AUTOSAR XML (schema 4-2-2)
standard types defined: UInt16, UInt32, UInt8, sint16, sint32, sint8, uint16, uint32, uint8
package /AUTOLIV/GlobalDictionary/ApplicationDataTypes
  25 x app type, all with category=VALUE, sw-calibration-access=READ-ONLY:
    UInt16_Appl: range phys 0..65535, raw 0..65535
    UInt32_Appl: range phys 0..4294967295, raw 0..4294967295
    UInt8_Appl: range phys 0..255, raw 0..255
    b8AlgorithmFlagsStatusType_Appl: compu {85=KB8_ALGO_FLAG_OFF (default), 170=KB8_ALGO_FLAG_ON (default)}, range raw 0..255
    b8BooleanType_Appl: compu {85=KU8_FALSE (default), 170=KU8_TRUE (default)}, range raw 0..255
    b8DefectStatusType_Appl: range raw 0..255
    b8IsCarAccelerationLowType_Appl: compu {85=KU8_FALSE (default), 170=KU8_TRUE (default)}, range raw 0..255  # Type of information about car acceleration state : low or not.
    b8IsCarCrankingActiveType_Appl: compu {85=KU8_FALSE (default), 170=KU8_TRUE (default)}, range raw 0..255  # To know if the car engine is cranking or not.
    b8IsCarCrashDetectedType_Appl: compu {85=KU8_FALSE (default), 170=KU8_TRUE (default)}, range raw 0..255  # Contains the information whether a car crash is detected or not.
    b8PyroActivationStatusType_Appl: compu {85=KB8_PYRO_DEVICE_NOT_ACTIVATED (default), 170=KB8_PYRO_DEVICE_ACTIVATED (default)} "List of status for the pyro device", range raw 0..255  # Type definition for the pyro device activation status
    s16AccelerationPedalPositionRateType_Appl: compu {raw=phys*2}, range raw -32768..32767
    s16AccelerationType_Appl: compu {raw=phys*16}, range raw -32768..32767
    s16AngleRateType_Appl: compu {raw=phys*256}, range raw -32768..32767
    s16BeltPosition_degType_Appl: range raw -32768..32767  # Belt position in °
    s16BeltPosition_mmType_Appl: range phys -32768..32767, raw -32768..32767  # Belt position in mm
    s16BrakePressureRateType_Appl: compu {raw=phys*16}, range raw -32768..32767
    s16HWAngleType_Appl: compu {raw=phys*16}, range raw -32768..32767
    s16HWRateType_Appl: compu {raw=phys*16}, range raw -32768..32767
    s16InternalTemperature_deg_Type_Appl: range phys -32768..32767, raw -32768..32767  # Type definition for the internal temperature in degrees Celcius
    s16MotorPowerOrderType_Appl: range phys -32768..32767, raw -32768..32767  # % of motor power [-X; +X] x = 6400
    s32BeltSpeed_deg_sType_Appl: range phys -2147483648..2147483647, raw -2147483648..2147483647  # Belt speed in °/s
    s32BeltSpeed_mm_sType_Appl: range phys -2147483648..2147483647, raw -2147483648..2147483647  # Belt speed in mm/s
    s32MotorCurrentInmAType_Appl: range phys -2147483648..2147483647, raw -2147483648..2147483647  # Value of the current in mAmps
    s32OrderValueType_Appl: range phys -2147483648..2147483647, raw -2147483648..2147483647  # Can be: - PWM - Current - Motor voltage
    s8MotorCurrentInAType_Appl: range phys -128..127, raw -128..127  # Signed current value in amps.
  application record data type stAbsoluteSystemTimeType_Appl: category=STRUCTURE, sw-calibration-access=READ-ONLY  # The absolute system time is composed of: - Absolute time in second - Offset in 100' second (0-&amp;gt;99) COVERS: PRO_SF03_1217
    application record element u32SystemTimeInSec: category=VALUE, type=UInt32_Appl
    application record element u8SystemTimeOffset: category=VALUE, type=UInt8_Appl
  43 x app type, all with category=VALUE:
    u16BoostPWMOrderType_Appl: sw-calibration-access=READ-ONLY, range phys 0..65535, raw 0..65535  # Boost PWM scaling is [0 - 512]
    u16BrakePressureType_Appl: sw-calibration-access=READ-ONLY, compu {raw=phys*16}, range raw 0..65535
    u16CurrentInLSBType_Appl: sw-calibration-access=READ-ONLY, range phys 0..65535, raw 0..65535  # Value of Motor Current in LSB (logical)
    u16InternalTemperatureType_Appl: sw-calibration-access=READ-ONLY, compu {raw=phys*4} "Computation method for internal temperature. 1LSB = 0,25°C", range raw 0..65535  # Type definition for the internal temperature
    u16NvmBlockIdType_Appl: sw-calibration-access=READ-ONLY, compu {0=NVM_BLOCK_ID_INTERNAL, 1=NVM_BLOCK_ID_CONFIG_ID, 2=NVM_BLOCK_ID_DEM, 3=NVM_BLOCK_ID_FBL_PROG_REQ_FLAG, 4=NVM_BLOCK_ID_FBL_RST_RESP_FLAG, 5=NVM_BLOCK_ID_FBL_VALIDITY_FLAGS, 6=NVM_BLOCK_ID_FBL_APPL_VALIDITY, 7=NVM_BLOCK_ID_FBL_SEC_ACCESS_DELAY_FLAG, 8=NVM_BLOCK_ID_FBL_SEC_ACCESS_INVALID_COUNT, 9=NVM_BLOCK_ID_FBL_FINGERPRINT_0, 10=NVM_BLOCK_ID_FBL_PROGCOUNTER_0, 11=NVM_BLOCK_ID_FBL_PROGATTEMPTS_0, 12=NVM_BLOCK_ID_FBL_FINGERPRINT_1, 13=NVM_BLOCK_ID_FBL_PROGCOUNTER_1, 14=NVM_BLOCK_ID_FBL_PROGATTEMPTS_1, 15=NVM_BLOCK_ID_FBL_FINGERPRINT_2, 16=NVM_BLOCK_ID_FBL_PROGCOUNTER_2, 17=NVM_BLOCK_ID_FBL_PROGATTEMPTS_2, 18=NVM_BLOCK_ID_ECU_LOCATION, 19=NVM_BLOCK_ID_ECU_LOCATION_MIRROR, 20=NVM_BLOCK_ID_BELT_ASSEMBLY_MANUF_DATE_AND_SN, 21=NVM_BLOCK_ID_HB_CALIBRATION, 22=NVM_BLOCK_ID_ECU_UNLOCK, 23=NVM_BLOCK_ID_PROCESS_MODE, 24=NVM_BLOCK_ID_HW_PART_NUMBER, 25=NVM_BLOCK_ID_AEE_TRACEABILITY, 26=NVM_BLOCK_ID_ECLK, 27=NVM_BLOCK_ID_ECC_COUNTERS, 28=NVM_BLOCK_ID_WARM_RESET, 29=NVM_BLOCK_ID_SYSTEM_CONTEXT_0, 30=NVM_BLOCK_ID_SYSTEM_CONTEXT_1, 31=NVM_BLOCK_ID_SYSTEM_CONTEXT_2, 32=NVM_BLOCK_ID_EXECUTION_COUNTERS, 33=NVM_BLOCK_ID_EXECUTION_COUNTERS_1, 34=NVM_BLOCK_ID_MEASUREMENT_FRAME_12_CONFIG, 35=NVM_BLOCK_ID_MEASUREMENT_FRAME_CONFIG, 36=NVM_BLOCK_ID_ECU_DYNAMIC_PROPERTIES, 37=NVM_BLOCK_ID_TESTS_PARAM, 38=NVM_BLOCK_ID_BPA_PARAM, 39=NVM_BLOCK_ID_BSR_PARAM, 40=NVM_BLOCK_ID_BELT_FUNCTIONS_ENABLE, 41=NVM_BLOCK_ID_SFR_PARAM, 42=NVM_BLOCK_ID_VDA, 43=NVM_BLOCK_ID_ATM_ENABLE_PARAM, 145=NVM_BLOCK_ID_EOL_PARAM, 146=NVM_BLOCK_ID_BFS_PRIO_PARAM, 147=NVM_BLOCK_ID_PID_PARAM, 148=NVM_BLOCK_ID_WEIGHT_REL_TABLE, 149=NVM_BLOCK_ID_WEIGHT_TENS0_TABLE, 150=NVM_BLOCK_ID_WEIGHT_TENS1_TABLE, 151=NVM_BLOCK_ID_WEIGHT_TENS2_TABLE, 152=NVM_BLOCK_ID_WEIGHT_TENS3_TABLE, 153=NVM_BLOCK_ID_INT_CURRENT_CORR, 154=NVM_BLOCK_ID_INT_CURRENT_TABLE, 155=NVM_BLOCK_ID_POWER_DEGRADATION, 156=NVM_BLOCK_ID_ECPL_ALPHA_TABLE, 157=NVM_BLOCK_ID_ECPL_BETA_TABLE, 158=NVM_BLOCK_ID_ECPL_OTHER_PARAM, 159=NVM_BLOCK_ID_BPA_MOTOR_CURRENT, 160=NVM_BLOCK_ID_VOLT_THRS, 161=NVM_BLOCK_ID_BATTERY_LOSS_DETECTION_THRS, 162=NVM_BLOCK_ID_BOOST, 163=NVM_BLOCK_ID_ECU_PROPERTIES, 164=NVM_BLOCK_ID_SW_SELF_PROTECTION_THRS, 165=NVM_BLOCK_ID_MOTOR_RESIST_PARAM, 166=NVM_BLOCK_ID_MAX_LIMIT, else NVM_BLOCK_ID_MAX_LIMIT}
    u16Resistance_mOhmType_Appl: sw-calibration-access=READ-ONLY, range phys 0..65535, raw 0..65535
    u16SampledSignalType_Appl: sw-calibration-access=READ-ONLY, range phys 0..65535, raw 0..65535
    u16StepDurationType_Appl: sw-calibration-access=READ-ONLY, range phys 0..65535, raw 0..65535  # profile step duration type
    u16VehicleSpeedType_Appl: sw-calibration-access=READ-ONLY, range phys 0..65535, raw 0..65535
    u16VoltageType_Appl: sw-calibration-access=READ-ONLY, range phys 0..65535, raw 0..65535
    u32DeficiencyLevelType_Appl: sw-calibration-access=READ-ONLY, range phys 0..4294967295, raw 0..4294967295  # Type of deficiency level variable managed by PAL S/W-c.
    u32ModeMaskType_Appl:
      sw-calibration-access=READ-ONLY
      compu {0=KU32_MASK_NO_MODE, 1048576=MMG_KU32_MASK_UNLOCKED_FACTORY_MODE, 2097152=MMG_KU32_MASK_AEC_INHIB_TENSIONING_CYCLES, 4194304=MMG_KU32_MASK_AEC_INHIB_ALL_CYCLES, 8388608=MMG_KU32_MASK_DEFAULT_VALUES, 16777216=MMG_KU32_MASK_NO_HALL_EFFECT_SENSOR, 33554432=MMG_KU32_MASK_NO_BOOSTER, 67108864=MMG_KU32_MASK_CRANKING, 134217728=MMG_KU32_MASK_BUS_OFF, 268435456=MMG_KU32_MASK_TENSIONING, 536870912=MMG_KU32_MASK_BELTFUNCTIONS_DELAY, 1073741824=MMG_KU32_MASK_POWER_VOLTAGE_UNSTABLE, 2147483648=MMG_KU32_MASK_CRITICAL_AT_NOK, 524288=MMG_KU32_MASK_BELTFUNCTIONS, 262144=MMG_KU32_MASK_BELTFUNCTIONS_DELAY_UV, else KU32_MASK_NO_MODE}
      range raw 0..4294967295
    u32RelativeSystemTimeType_Appl: sw-calibration-access=READ-ONLY, range phys 0..4294967295, raw 0..4294967295  # Type of system time (resolution : 10 ms) COVERS: PRO_SF03_1230
    u32ResetCauseType_Appl:  # Type for the reset causes handled by the PP Platform
      sw-calibration-access=READ-ONLY
      compu {1=KU32_POWER_ON_RESET_MASK, 2=KU32_BATTERY_LOSS_MASK, 4=KU32_CRYSTAL_FAILURE_MASK, 8=KU32_PLL_FAILURE_MASK, 16=KU32_INTERNAL_WDG_MASK, 32=KU32_SW_INTERNAL_WDG_MASK, 64=KU32_SW_RESET_MASK, 128=KU32_BTLD_RESET_MASK, 256=KU32_ECC_RAM_MASK, 512=KU32_ECC_PFLASH_MASK, 1024=KU32_OS_EXCEPTION_MASK, 2048=KU32_INVALID_INTERRUPT_MASK, 4096=KU32_WAKE_UP_EVENT_MASK, 8192=KU32_SW_WDG_TEST_MASK, 16384=KU32_ECC_UNIDENTIFIED_MASK, 0=KU32_RESET_CAUSE_UNKNOWN, 32768=KU32_ECC_E2P_MASK, 65536=KU32_MACHINE_EXCEPTION_MASK, 131072=KU32_STACK_OVERFLOW_MASK, 262144=KU32_RAM_DATA_CORRUPTED} "List of reset causes handled by the PP4G SW"
      range raw 0..4294967295
    u32ResetReasonNotificationStatusType_Appl: sw-calibration-access=READ-ONLY, compu {85=KU32_RESET_CAUSE_INACTIVE (default), 170=KU32_RESET_CAUSE_ACTIVE (default)} "Scaling to give the status of the reset cause which is notified", range raw 0..4294967295  # Type to give the status of the reset cause which is notified
    u32ResetReasonNotificationType_Appl:  # Type to allow the notification to RCM by other SW modules that a reset will be managed
      sw-calibration-access=READ-ONLY
      compu {0=KU32_INVALID_INTERRUPT_NOTIFICATION, 1=KU32_OS_EXCEPTION_NOTIFICATION, 2=KU32_BATTERY_LOSS_NOTIFICATION, 3=KU32_ECC_RAM_NOTIFICATION, 4=KU32_ECC_PFLASH_NOTIFICATION, 5=KU32_ECC_E2P_NOTIFICATION, 6=KU32_MACHINE_EXCEPTION_NOTIFICATION, 7=KU32_SW_IWD_NOTIFICATION, 8=KU32_SW_WDG_TEST_NOTIFICATION, 9=KU32_WAKE_UP_EVENT_NOTIFICATION, 10=KU32_ECC_UNIDENTIFIED_NOTIFICATION, 11=KU32_BTLD_RESET_NOTIFICATION, 12=KU32_STACK_OVERFLOW_NOTIFICATION, 13=KU32_RAM_DATA_CORRUPTED_NOTIFICATION, 14=KU32_MAX_RESET_NOTIFICATION} "list of reset causes handled by SW in order to notify RCM that a reset will occur for the corresponding reason"
      range raw 0..4294967295
    u8AccelerationPedalPositionType_Appl: sw-calibration-access=READ-ONLY, compu {raw=phys*2}, range raw 0..255
    u8AutoTestIdType_Appl: sw-calibration-access=READ-ONLY, compu {0=ATM_KU8_ID_TEST_ADC, 1=ATM_KU8_ID_TEST_HIGH_SIDE_SWITCH, 2=ATM_KU8_ID_TEST_DRIVER_COMMAND, 3=ATM_KU8_ID_TEST_MOSFET_HIGH_SHORT_CIRCUIT, 4=ATM_KU8_ID_TEST_MOSFET_LOW_SHORT_CIRCUIT, 5=ATM_KU8_ID_TEST_MOTOR_DISCONNECTION, 6=ATM_KU8_ID_TEST_DRIVER_SELF_PROTECTION, 7=ATM_KU8_ID_TEST_MOSFET_OPEN_CIRCUIT, 8=ATM_KU8_ID_TEST_PRELIMINARY_BOOST, 9=ATM_KU8_ID_TEST_VBOOST, 10=ATM_KU8_ID_PFLASH_MEMORY_CORRUPTION, 11=ATM_KU8_ID_TEST_HALL_EFFECT_SENSORS, 12=ATM_KU8_ID_TEST_MOTOR_CURRENT, 13=ATM_KU8_ID_TEST_MOTOR_BLOCKED, 14=ATM_KU8_ID_TEST_MOTOR_TEMPERATURE, 15=ATM_KU8_ID_TEST_SBC_TEMPERATURE, 16=ATM_KU8_ID_TEST_MOTOR_SHORT_CIRCUIT, 17=ATM_KU8_ID_TEST_PWM_ORDER, 18=ATM_KU8_ID_TEST_UNDER_VOLTAGE_POWER, 19=ATM_KU8_ID_TEST_OVER_VOLTAGE_POWER, 20=ATM_KU8_ID_TEST_UNDER_VOLTAGE_TENSIONING_POWER, 21=ATM_KU8_ID_TEST_OVER_VOLTAGE_LOGIC, 22=ATM_KU8_ID_TEST_UNDER_VOLTAGE_LOGIC, 23=ATM_KU8_ID_TEST_IMPLAUSIBLE_BATTERY_LEVEL, 24=ATM_KU8_ID_SPI_GENERIC_AEC_CFG, 25=ATM_KU8_ID_EXT_WDG_OUT_OF_ORDER, 26=ATM_KU8_ID_FLS_OUT_OF_ORDER, 27=ATM_KU8_ID_NVM_NOT_PROG, 28=ATM_KU8_ID_NVM_MEMORY_CORRUPTION, 29=ATM_KU8_ID_RAM_MEMORY_CORRUPTION, 30=ATM_KU8_ID_TFLASH_MEMORY_CORRUPTION, 31=ATM_KU8_ID_STACK_OVERFLOW, 32=ATM_KU8_ID_CAN_BUS_OFF, 33=ATM_KU8_ID_SUPPLY_VOLTAGE_UNDER_VEHICLE_VOLTAGE, 34=ATM_KU8_ID_RESET_CAUSE, 35=ATM_KU8_ID_END_OF_LIFE_LOW_FORCE, 36=ATM_KU8_ID_END_OF_LIFE_HIGH_FORCE, 37=ATM_KU8_ID_END_OF_LIFE_COMFORT, 38=ATM_KU8_ID_END_OF_LIFE_HAPTIC_WARNING, 39=ATM_KU8_ID_TEST_SBC_CONFIGURATION_EXT, 40=ATM_KU8_ID_TEST_NVM_CHECKSUM, 41=ATM_KU8_ID_TEST_BATTERY_SURVEY}  # Identifier of auto test
    u8BatteryVoltageSurveyStatusType_Appl: sw-calibration-access=READ-ONLY, compu {0=KU8_BATTERY_STABLE (default), 1=KU8_BATTERY_UNSTABLE (default)}, range raw 0..255  # Define the different battery states: -Stable/Unstable
    u8BeltParkingAuthorizationStateType_Appl: sw-calibration-access=READ-ONLY, compu {0=KU8_BP_AUTHORIZATION_STATE_INIT (default), 1=KU8_BP_AUTHORIZATION_STATE_OPS_ALLOWED (default), 2=KU8_BP_AUTHORIZATION_STATE_IDLE (default), 3=KU8_BP_AUTHORIZATION_STATE_BPDO_ALLOWED (default), 4=KU8_BP_AUTHORIZATION_STATE_BPDC_ALLOWED (default), 5=KU8_BP_AUTHORIZATION_STATE_BUCKLED (default)}, range raw 0..255
    u8BeltSlackStatusType_Appl: sw-calibration-access=READ-ONLY, compu {0=KU8_BELT_SLACK_OFF (default), 1=KU8_BELT_SLACK_ON (default), 2=KU8_BELT_SLACK_NOT_DEFINED (default), 3=KU8_BELT_SLACK_INVALID (default)} "Belt Slack status", range raw 0..255
    u8CanNmStateType_Appl: sw-calibration-access=READ-ONLY, compu {1=CAN_NM_U8_BUS_SLEEP, 2=CAN_NM_U8_REPEAT_MESSAGE, 4=CAN_NM_U8_NORMAL_OPERATION, 8=CAN_NM_U8_READY_SLEEP, 16=CAN_NM_U8_PREPARE_SLEEP, 32=CAN_NM_U8_OFF, else CAN_NM_U8_OFF}
    u8CycleNumberType_Appl:
      sw-calibration-access=READ-ONLY
      compu {0=KU8_BELT_FUNCTION_00 (default), 1=KU8_BELT_FUNCTION_01 (default), 2=KU8_BELT_FUNCTION_02 (default), 3=KU8_BELT_FUNCTION_03 (default), 4=KU8_BELT_FUNCTION_04 (default), 5=KU8_BELT_FUNCTION_05 (default), 6=KU8_BELT_FUNCTION_06 (default), 7=KU8_BELT_FUNCTION_07 (default), 8=KU8_BELT_FUNCTION_08 (default), 9=KU8_BELT_FUNCTION_09 (default), 10=KU8_BELT_FUNCTION_10 (default), 11=KU8_BELT_FUNCTION_11 (default), 12=KU8_BELT_FUNCTION_12 (default), 13=KU8_BELT_FUNCTION_13 (default), 14=KU8_BELT_FUNCTION_14 (default), 15=KU8_BELT_FUNCTION_15 (default), 16=KU8_BELT_FUNCTION_16 (default), 17=KU8_BELT_FUNCTION_17 (default), 255=KU8_NO_CYCLE (default), 18=KU8_BELT_FUNCTION_18 (default), 19=KU8_BELT_FUNCTION_19 (default), 20=KU8_BELT_FUNCTION_20 (default), 21=KU8_NB_MAX_CYCLES (default)}
      range raw 0..255
    u8DoorSwitchStatusType_Appl: sw-calibration-access=READ-ONLY, compu {170=KU8_DOOR_SWITCH_OPENED (default), 85=KU8_DOOR_SWITCH_CLOSED (default), 255=KU8_DOOR_SWITCH_NOT_DEFINED (default)} "Status of the door switch", range raw 0..255  # Data type containing the information whether the belt is fastened or not (or not defined).
    u8EccErrorStatusType_Appl: sw-calibration-access=READ-ONLY, compu {1=KU8_ECC_STATUS_ACTIVE (default), 128=KU8_ECC_STATUS_DETECTED_SINCE_LAST_RESET (default), 0=KU8_ECC_STATUS_NONE (default)} "List of possible status of the ECC error", range raw 0..255  # Type defintion of the status of the Ecc error
    u8EccErrorType_Appl: sw-calibration-access=READ-ONLY, compu {1=KU8_ECC_ERROR_PFLASH (default), 3=KU8_ECC_ERROR_RAM (default), 0=KU8_ECC_ERROR_NONE (default), 2=KU8_ECC_ERROR_DFLASH (default), 4=KU8_ECC_ERROR_TFLASH (default), 5=KU8_ECC_ERROR_UNIDENTIFIED (default), 6=KU8_ECC_ERROR_NUMBER (default)} "List of ECC error which can be detected by the micro-controler", range raw 0..255  # Type definition for ECC errors
    u8EsmEventIdType_Appl: sw-calibration-access=READ-ONLY, compu {0=ESM_U8_WAKE_UP_REQUEST_EVENT, 1=ESM_U8_KEEP_ALIVE_ABSENT_EVENT, 2=ESM_U8_ECU_SHUTDOWN_ON_GOING_EVENT, 3=ESM_U8_GO_TO_SLEEP_REQUEST_EVENT, 4=ESM_U8_FORCE_SHUTDOWN, 5=ESM_U8_NB_EVENTS, else ESM_U8_WAKE_UP_REQUEST_EVENT}
    u8EsmStateType_Appl: sw-calibration-access=READ-ONLY, compu {1=ESM_U8_STATE_WAKE_UP, 2=ESM_U8_STATE_RUN, 4=ESM_U8_STATE_POST_RUN, 8=ESM_U8_STATE_SHUTDOWN, else ESM_U8_STATE_WAKE_UP}
    u8HapticRequestType_Appl: sw-calibration-access=READ-ONLY, compu {0=KU8_HAPTIC_REQUEST_0 (default), 1=KU8_HAPTIC_REQUEST_1 (default), 2=KU8_HAPTIC_REQUEST_2 (default), 3=KU8_NO_HAPTIC_REQUEST (default)}, range raw 0..255
    u8KlemmenStatusType_Appl: sw-calibration-access=READ-ONLY, compu {2=KU8_KLEMMEN_ACCESSORY (default), 1=KU8_KLEMMEN_OFF (default), 3=KU8_KLEMMEN_ON (default), 0=KU8_KLEMMEN_LOCK (default), 4=KU8_KLEMMEN_START (default)}
    u8ModeStatusType_Appl: sw-calibration-access=READ-ONLY, compu {170=KU8_MODE_STATUS_ON (default), 85=KU8_MODE_STATUS_OFF (default)}, range raw 0..255
    u8MotorStageStatusType_Appl: sw-calibration-access=READ-ONLY, compu {85=KU8_MOTOR_STAGE_EMERGENCY_DEACTIVATION (default), 170=KU8_MOTOR_STAGE_ACTIVATION (default)}, range raw 0..255
    u8OrdersListType_Appl: sw-calibration-access=READ-ONLY, compu {2=KU8_ORDER_CURRENT_REGULATION (default), 4=KU8_ORDER_MOTOR_VOLTAGE (default), 32=KU8_ORDER_PID_MOTOR (default), 64=KU8_ORDER_HIGH_POWER (default), 8=KU8_ORDER_RESERVED_1 (default), 1=KU8_ORDER_PWM (default), 16=KU8_ORDER_PID_SUPPLY (default), 128=KU8_ORDER_RESERVED_2 (default)}, range raw 0..255
    u8PreCrashRequestType_Appl: sw-calibration-access=READ-ONLY, compu {0=KU8_PRECRASH_REQUEST_0 (default), 1=KU8_PRECRASH_REQUEST_1 (default), 2=KU8_PRECRASH_REQUEST_2 (default), 3=KU8_PRECRASH_REQUEST_3 (default), 4=KU8_PRECRASH_REQUEST_4 (default), 5=KU8_PRECRASH_REQUEST_5 (default), 6=KU8_PRECRASH_REQUEST_6 (default), 7=KU8_PRECRASH_REQUEST_7 (default), 255=KU8_NO_PRECRASH_REQUEST (default)}, range raw 0..255
    u8PreCrashSeverityLevelType_Appl:
      sw-calibration-access=READ-ONLY
      compu {0=KU8_PRECRASH_SEVERITY_LEVEL_1 (default), 1=KU8_PRECRASH_SEVERITY_LEVEL_2 (default), 2=KU8_PRECRASH_SEVERITY_LEVEL_3 (default), 3=KU8_PRECRASH_SEVERITY_LEVEL_4 (default), 4=KU8_PRECRASH_SEVERITY_LEVEL_5 (default), 5=KU8_PRECRASH_SEVERITY_LEVEL_6 (default), 6=KU8_PRECRASH_SEVERITY_LEVEL_7 (default), 7=KU8_PRECRASH_SEVERITY_LEVEL_8 (default), 255=KU8_NO_PRECRASH_SEVERITY_LEVEL (default)}
      range raw 0..255
    u8PwmChannelId_Appl: sw-calibration-access=READ-ONLY, compu {0=PWM_KU8_CH_ID_HB_P, 1=PWM_KU8_CH_ID_HB_N, 2=PWM_KU8_CH_ID_BOOST_DRIVER, 3=PWM_KU8_CH_ID_BOOST_CP, 4=PWM_KU8_CH_ID_MAX, else PWM_KU8_CH_ID_MAX}, range raw 0..4
    u8RequestResultType_Appl
    u8RetractionStatusType_Appl: sw-calibration-access=READ-ONLY, compu {170=KU8_SPRING_FORCE_HARD_ENOUGH (default), 85=KU8_SPRING_FORCE_NOT_HARD_ENOUGH (default), 255=KU8_SPRING_FORCE_ON_GOING (default)}, range raw 0..255
    u8SeverityLevelType_Appl: sw-calibration-access=READ-ONLY, range raw 0..255
    u8StepNumberType_Appl: sw-calibration-access=READ-ONLY, range phys 0..255, raw 0..255  # Type definition for the step number
    u8TestResultType_Appl: sw-calibration-access=READ-ONLY, compu {1=KU8_ATM_TEST_OK, 2=KU8_ATM_TEST_NOK, 4=KU8_ATM_TEST_NOT_DECIDED, 8=KU8_ATM_TEST_NON_EXISTENT, 16=KU8_ATM_TEST_BAD_CONDITIONS}, range raw 0..255
    u8TriggeringSourceType_Appl: sw-calibration-access=READ-ONLY, compu {0=KU8_TRIGGERING_SOURCE_NONE (default), 1=KU8_TRIGGERING_SOURCE_VEHICLE (default), 2=KU8_TRIGGERING_SOURCE_TESTER (default)} "BIT FIELD List of sources which can request a belt function triggering.", range raw 0..255
    u8lBuckleSwitchStatusType_Appl: sw-calibration-access=READ-ONLY, compu {170=KU8_BUCKLE_SWITCH_OPENED (default), 85=KU8_BUCKLE_SWITCH_CLOSED (default), 255=KU8_BUCKLE_SWITCH_NOT_DEFINED (default)} "Status of the buckle switch", range raw 0..255  # Data type containing the information whether the belt is fastened or not (or not defined).
package /AUTOLIV/GlobalDictionary/Constants
  36 x constant specification:
    APPLINIT_KB8_ALGO_FLAG_FALSE: value-spec=85
    APPLINIT_KB8_BOOLEAN_FALSE: value-spec=85
    APPLINIT_KB8_CAR_ACCEL_LOW_TRUE: value-spec=170
    APPLINIT_KB8_CAR_CRANKING_ACTIVE_TRUE: value-spec=170
    APPLINIT_KB8_CAR_CRASH_DETECTED_FALSE: value-spec=85
    APPLINIT_KB8_DEFECT_STATUS_FALSE: value-spec=85
    APPLINIT_KS16_ACCELERATION_ZERO: value-spec=0
    APPLINIT_KS16_ACCEL_PEDAL_POS_RATE_ZERO: value-spec=0
    APPLINIT_KS16_ANGLE_RATE_ZERO: value-spec=0
    APPLINIT_KS16_BRAKE_PRESSURE_RATE_ZERO: value-spec=0
    APPLINIT_KS16_HW_ANGLE_ZERO: value-spec=0
    APPLINIT_KS16_HW_RATE_ZERO: value-spec=0
    APPLINIT_KS16_MOTOR_POWER_ORDER_ZERO: value-spec=0
    APPLINIT_KS32_ORDER_VALUE_ZERO: value-spec=0
    APPLINIT_KU16_BRAKE_PRESSURE_ZERO: value-spec=0
    APPLINIT_KU16_STEP_DURATION_ZERO: value-spec=0
    APPLINIT_KU16_VEHICLE_SPEED_ZERO: value-spec=0
    APPLINIT_KU32_DEFICIENCY_LEVEL_ZERO: value-spec=0
    APPLINIT_KU32_RESET_CAUSE_UNKNOWN: value-spec=0
    APPLINIT_KU8_ACCEL_PEDAL_POS_ZERO: value-spec=0
    APPLINIT_KU8_BELT_PARKING_AUTHORIZATION_STATE_INIT: value-spec=0
    APPLINIT_KU8_BELT_SLACK_STATUS_NOT_DEFINED: value-spec=2
    APPLINIT_KU8_BUCKLE_SWITCH_STATUS_NOT_DEFINED: value-spec=255
    APPLINIT_KU8_CYCLE_NUMBER_NONE: value-spec=255
    APPLINIT_KU8_DOOR_SWITCH_STATUS_NOT_DEFINED: value-spec=255
    APPLINIT_KU8_HAPTIC_REQUEST_NO: value-spec=3
    APPLINIT_KU8_KLEMMEN_STATUS_ZERO: value-spec=0
    APPLINIT_KU8_MOTOR_STAGE_STATUS_ACTIVATION: value-spec=170
    APPLINIT_KU8_ORDERS_LIST_ZERO: value-spec=0
    APPLINIT_KU8_PRE_CRASH_REQUEST_NO_REQUEST: value-spec=255
    APPLINIT_KU8_PRE_CRASH_SEVERITY_LEVEL_NO: value-spec=255
    APPLINIT_KU8_REPETITION_COUNTER_ZERO: value-spec=0
    APPLINIT_KU8_RETRACTION_STATUS_ONGOING: value-spec=255
    APPLINIT_KU8_SEVERITY_LEVEL_ZERO: value-spec=0
    APPLINIT_KU8_STEP_NUMBER_NONE: value-spec=255
    APPLINIT_KU8_TRIGGERING_SOURCE_NO: value-spec=0
  constant specification mapping set ConstantsMappingSet_PP4G
    mappings:
      appl-constant=APPLINIT_KB8_ALGO_FLAG_FALSE, impl-constant=IMPLINIT_KB8_ALGO_FLAG_FALSE
      appl-constant=APPLINIT_KB8_BOOLEAN_FALSE, impl-constant=IMPLINIT_KB8_BOOLEAN_FALSE
      appl-constant=APPLINIT_KB8_CAR_ACCEL_LOW_TRUE, impl-constant=IMPLINIT_KB8_CAR_ACCEL_LOW_TRUE
      appl-constant=APPLINIT_KB8_CAR_CRANKING_ACTIVE_TRUE, impl-constant=IMPLINIT_KB8_CAR_CRANKING_ACTIVE_TRUE
      appl-constant=APPLINIT_KB8_CAR_CRASH_DETECTED_FALSE, impl-constant=IMPLINIT_KB8_CAR_CRASH_DETECTED_FALSE
      appl-constant=APPLINIT_KB8_DEFECT_STATUS_FALSE, impl-constant=IMPLINIT_KB8_DEFECT_STATUS_FALSE
      appl-constant=APPLINIT_KS16_ACCELERATION_ZERO, impl-constant=IMPLINIT_KS16_ACCELERATION_ZERO
      appl-constant=APPLINIT_KS16_ACCEL_PEDAL_POS_RATE_ZERO, impl-constant=IMPLINIT_KS16_ACCEL_PEDAL_POS_RATE_ZERO
      appl-constant=APPLINIT_KS16_ANGLE_RATE_ZERO, impl-constant=IMPLINIT_KS16_ANGLE_RATE_ZERO
      appl-constant=APPLINIT_KS16_BRAKE_PRESSURE_RATE_ZERO, impl-constant=IMPLINIT_KS16_BRAKE_PRESSURE_RATE_ZERO
      appl-constant=APPLINIT_KS16_HW_ANGLE_ZERO, impl-constant=IMPLINIT_KS16_HW_ANGLE_ZERO
      appl-constant=APPLINIT_KS16_HW_RATE_ZERO, impl-constant=IMPLINIT_KS16_HW_RATE_ZERO
      appl-constant=APPLINIT_KS16_MOTOR_POWER_ORDER_ZERO, impl-constant=IMPLINIT_KS16_MOTOR_POWER_ORDER_ZERO
      appl-constant=APPLINIT_KS32_ORDER_VALUE_ZERO, impl-constant=IMPLINIT_KS32_ORDER_VALUE_ZERO
      appl-constant=APPLINIT_KU16_BRAKE_PRESSURE_ZERO, impl-constant=IMPLINIT_KU16_BRAKE_PRESSURE_ZERO
      appl-constant=APPLINIT_KU16_STEP_DURATION_ZERO, impl-constant=IMPLINIT_KU16_STEP_DURATION_ZERO
      appl-constant=APPLINIT_KU16_VEHICLE_SPEED_ZERO, impl-constant=IMPLINIT_KU16_VEHICLE_SPEED_ZERO
      appl-constant=APPLINIT_KU32_DEFICIENCY_LEVEL_ZERO, impl-constant=IMPLINIT_KU32_DEFICIENCY_LEVEL_ZERO
      appl-constant=APPLINIT_KU32_RESET_CAUSE_UNKNOWN, impl-constant=IMPLINIT_KU32_RESET_CAUSE_UNKNOWN
      appl-constant=APPLINIT_KU8_ACCEL_PEDAL_POS_ZERO, impl-constant=IMPLINIT_KU8_ACCEL_PEDAL_POS_ZERO
      appl-constant=APPLINIT_KU8_BELT_PARKING_AUTHORIZATION_STATE_INIT, impl-constant=IMPLINIT_KU8_BELT_PARKING_AUTHORIZATION_STATE_INIT
      appl-constant=APPLINIT_KU8_BELT_SLACK_STATUS_NOT_DEFINED, impl-constant=IMPLINIT_KU8_BELT_SLACK_STATUS_NOT_DEFINED
      appl-constant=APPLINIT_KU8_BUCKLE_SWITCH_STATUS_NOT_DEFINED, impl-constant=IMPLINIT_KU8_BUCKLE_SWITCH_STATUS_NOT_DEFINED
      appl-constant=APPLINIT_KU8_CYCLE_NUMBER_NONE, impl-constant=IMPLINIT_KU8_CYCLE_NUMBER_NONE
      appl-constant=APPLINIT_KU8_DOOR_SWITCH_STATUS_NOT_DEFINED, impl-constant=IMPLINIT_KU8_DOOR_SWITCH_STATUS_NOT_DEFINED
      appl-constant=APPLINIT_KU8_HAPTIC_REQUEST_NO, impl-constant=IMPLINIT_KU8_HAPTIC_REQUEST_NO
      appl-constant=APPLINIT_KU8_KLEMMEN_STATUS_ZERO, impl-constant=IMPLINIT_KU8_KLEMMEN_STATUS_ZERO
      appl-constant=APPLINIT_KU8_MOTOR_STAGE_STATUS_ACTIVATION, impl-constant=IMPLINIT_KU8_MOTOR_STAGE_STATUS_ACTIVATION
      appl-constant=APPLINIT_KU8_ORDERS_LIST_ZERO, impl-constant=IMPLINIT_KU8_ORDERS_LIST_ZERO
      appl-constant=APPLINIT_KU8_PRE_CRASH_REQUEST_NO_REQUEST, impl-constant=IMPLINIT_KU8_PRE_CRASH_REQUEST_NO_REQUEST
      appl-constant=APPLINIT_KU8_PRE_CRASH_SEVERITY_LEVEL_NO, impl-constant=IMPLINIT_KU8_PRE_CRASH_SEVERITY_LEVEL_NO
      appl-constant=APPLINIT_KU8_REPETITION_COUNTER_ZERO, impl-constant=IMPLINIT_KU8_REPETITION_COUNTER_ZERO
      appl-constant=APPLINIT_KU8_RETRACTION_STATUS_ONGOING, impl-constant=IMPLINIT_KU8_RETRACTION_STATUS_ONGOING
      appl-constant=APPLINIT_KU8_SEVERITY_LEVEL_ZERO, impl-constant=IMPLINIT_KU8_SEVERITY_LEVEL_ZERO
      appl-constant=APPLINIT_KU8_STEP_NUMBER_NONE, impl-constant=IMPLINIT_KU8_STEP_NUMBER_NONE
      appl-constant=APPLINIT_KU8_TRIGGERING_SOURCE_NO, impl-constant=IMPLINIT_KU8_TRIGGERING_SOURCE_NO
      appl-constant=APPLINIT_KU8_UINT8_ZERO, impl-constant=IMPLINIT_KU8_UINT8_ZERO
  36 x constant specification:
    IMPLINIT_KB8_ALGO_FLAG_FALSE: value-spec=85
    IMPLINIT_KB8_BOOLEAN_FALSE: value-spec=85
    IMPLINIT_KB8_CAR_ACCEL_LOW_TRUE: value-spec=170
    IMPLINIT_KB8_CAR_CRANKING_ACTIVE_TRUE: value-spec=170
    IMPLINIT_KB8_CAR_CRASH_DETECTED_FALSE: value-spec=85
    IMPLINIT_KB8_DEFECT_STATUS_FALSE: value-spec=85
    IMPLINIT_KS16_ACCELERATION_ZERO: value-spec=0
    IMPLINIT_KS16_ACCEL_PEDAL_POS_RATE_ZERO: value-spec=0
    IMPLINIT_KS16_ANGLE_RATE_ZERO: value-spec=0
    IMPLINIT_KS16_BRAKE_PRESSURE_RATE_ZERO: value-spec=0
    IMPLINIT_KS16_HW_ANGLE_ZERO: value-spec=0
    IMPLINIT_KS16_HW_RATE_ZERO: value-spec=0
    IMPLINIT_KS16_MOTOR_POWER_ORDER_ZERO: value-spec=0
    IMPLINIT_KS32_ORDER_VALUE_ZERO: value-spec=0
    IMPLINIT_KU16_BRAKE_PRESSURE_ZERO: value-spec=0
    IMPLINIT_KU16_STEP_DURATION_ZERO: value-spec=0
    IMPLINIT_KU16_VEHICLE_SPEED_ZERO: value-spec=0
    IMPLINIT_KU32_DEFICIENCY_LEVEL_ZERO: value-spec=0
    IMPLINIT_KU32_RESET_CAUSE_UNKNOWN: value-spec=0
    IMPLINIT_KU8_ACCEL_PEDAL_POS_ZERO: value-spec=0
    IMPLINIT_KU8_BELT_PARKING_AUTHORIZATION_STATE_INIT: value-spec=0
    IMPLINIT_KU8_BELT_SLACK_STATUS_NOT_DEFINED: value-spec=2
    IMPLINIT_KU8_BUCKLE_SWITCH_STATUS_NOT_DEFINED: value-spec=255
    IMPLINIT_KU8_CYCLE_NUMBER_NONE: value-spec=255
    IMPLINIT_KU8_DOOR_SWITCH_STATUS_NOT_DEFINED: value-spec=255
    IMPLINIT_KU8_HAPTIC_REQUEST_NO: value-spec=3
    IMPLINIT_KU8_KLEMMEN_STATUS_ZERO: value-spec=0
    IMPLINIT_KU8_MOTOR_STAGE_STATUS_ACTIVATION: value-spec=170
    IMPLINIT_KU8_ORDERS_LIST_ZERO: value-spec=0
    IMPLINIT_KU8_PRE_CRASH_REQUEST_NO_REQUEST: value-spec=255
    IMPLINIT_KU8_PRE_CRASH_SEVERITY_LEVEL_NO: value-spec=255
    IMPLINIT_KU8_REPETITION_COUNTER_ZERO: value-spec=0
    IMPLINIT_KU8_RETRACTION_STATUS_ONGOING: value-spec=255
    IMPLINIT_KU8_SEVERITY_LEVEL_ZERO: value-spec=0
    IMPLINIT_KU8_STEP_NUMBER_NONE: value-spec=255
    IMPLINIT_KU8_TRIGGERING_SOURCE_NO: value-spec=0
package /AUTOLIV/GlobalDictionary/DataTypeMappingSet
  data type mapping set DataTypeMappingSet_PP4G
    data-type-maps:
      application-data-type=u8CanNmStateType_Appl, implementation-data-type=u8CanNmStateType
      application-data-type=u8EsmStateType_Appl, implementation-data-type=u8EsmStateType
      application-data-type=u8EsmEventIdType_Appl, implementation-data-type=u8EsmEventIdType
      application-data-type=stAbsoluteSystemTimeType_Appl, implementation-data-type=stAbsoluteSystemTimeType
      application-data-type=u16VoltageType_Appl, implementation-data-type=u16VoltageType
      application-data-type=u32DeficiencyLevelType_Appl, implementation-data-type=u32DeficiencyLevelType
      application-data-type=u32ModeMaskType_Appl, implementation-data-type=u32ModeMaskType
      application-data-type=u32RelativeSystemTimeType_Appl, implementation-data-type=u32RelativeSystemTimeType
      application-data-type=u32ResetCauseType_Appl, implementation-data-type=u32ResetCauseType
      application-data-type=u32ResetReasonNotificationStatusType_Appl, implementation-data-type=u32ResetReasonNotificationStatusType
      application-data-type=u32ResetReasonNotificationType_Appl, implementation-data-type=u32ResetReasonNotificationType
      application-data-type=u8AccelerationPedalPositionType_Appl, implementation-data-type=u8AccelerationPedalPositionType
      application-data-type=u8AutoTestIdType_Appl, implementation-data-type=u8AutoTestIdType
      application-data-type=u8BatteryVoltageSurveyStatusType_Appl, implementation-data-type=u8BatteryVoltageSurveyStatusType
      application-data-type=u8BeltParkingAuthorizationStateType_Appl, implementation-data-type=u8BeltParkingAuthorizationStateType
      application-data-type=u8BeltSlackStatusType_Appl, implementation-data-type=u8BeltSlackStatusType
      application-data-type=u8CycleNumberType_Appl, implementation-data-type=u8CycleNumberType
      application-data-type=u8DoorSwitchStatusType_Appl, implementation-data-type=u8DoorSwitchStatusType
      application-data-type=u8EccErrorStatusType_Appl, implementation-data-type=u8EccErrorStatusType
      application-data-type=u8EccErrorType_Appl, implementation-data-type=u8EccErrorType
      application-data-type=u8HapticRequestType_Appl, implementation-data-type=u8HapticRequestType
      application-data-type=u8KlemmenStatusType_Appl, implementation-data-type=u8KlemmenStatusType
      application-data-type=u8lBuckleSwitchStatusType_Appl, implementation-data-type=u8lBuckleSwitchStatusType
      application-data-type=u8ModeStatusType_Appl, implementation-data-type=u8ModeStatusType
      application-data-type=u8MotorStageStatusType_Appl, implementation-data-type=u8MotorStageStatusType
      application-data-type=u8OrdersListType_Appl, implementation-data-type=u8OrdersListType
      application-data-type=u8PreCrashRequestType_Appl, implementation-data-type=u8PreCrashRequestType
      application-data-type=u8PreCrashSeverityLevelType_Appl, implementation-data-type=u8PreCrashSeverityLevelType
      application-data-type=u8RetractionStatusType_Appl, implementation-data-type=u8RetractionStatusType
      application-data-type=u8SeverityLevelType_Appl, implementation-data-type=u8SeverityLevelType
      application-data-type=u8StepNumberType_Appl, implementation-data-type=u8StepNumberType
      application-data-type=u8TestResultType_Appl, implementation-data-type=u8TestResultType
      application-data-type=u8TriggeringSourceType_Appl, implementation-data-type=u8TriggeringSourceType
      application-data-type=UInt16_Appl, implementation-data-type=UInt16
      application-data-type=UInt32_Appl, implementation-data-type=UInt32
      application-data-type=UInt8_Appl, implementation-data-type=UInt8
      application-data-type=b8AlgorithmFlagsStatusType_Appl, implementation-data-type=b8AlgorithmFlagsStatusType
      application-data-type=b8BooleanType_Appl, implementation-data-type=b8BooleanType
      application-data-type=b8DefectStatusType_Appl, implementation-data-type=b8DefectStatusType
      application-data-type=b8IsCarAccelerationLowType_Appl, implementation-data-type=b8IsCarAccelerationLowType
      application-data-type=b8IsCarCrankingActiveType_Appl, implementation-data-type=b8IsCarCrankingActiveType
      application-data-type=b8IsCarCrashDetectedType_Appl, implementation-data-type=b8IsCarCrashDetectedType
      application-data-type=b8PyroActivationStatusType_Appl, implementation-data-type=b8PyroActivationStatusType
      application-data-type=s16AccelerationPedalPositionRateType_Appl, implementation-data-type=s16AccelerationPedalPositionRateType
      application-data-type=s16AccelerationType_Appl, implementation-data-type=s16AccelerationType
      application-data-type=s16AngleRateType_Appl, implementation-data-type=s16AngleRateType
      application-data-type=s16BeltPosition_degType_Appl, implementation-data-type=s16BeltPosition_degType
      application-data-type=s16BeltPosition_mmType_Appl, implementation-data-type=s16BeltPosition_mmType
      application-data-type=s16BrakePressureRateType_Appl, implementation-data-type=s16BrakePressureRateType
      application-data-type=s16HWAngleType_Appl, implementation-data-type=s16HWAngleType
      application-data-type=s16HWRateType_Appl, implementation-data-type=s16HWRateType
      application-data-type=s16InternalTemperature_deg_Type_Appl, implementation-data-type=s16InternalTemperature_deg_Type
      application-data-type=s16MotorPowerOrderType_Appl, implementation-data-type=s16MotorPowerOrderType
      application-data-type=s32BeltSpeed_deg_sType_Appl, implementation-data-type=s32BeltSpeed_deg_sType
      application-data-type=s32BeltSpeed_mm_sType_Appl, implementation-data-type=s32BeltSpeed_mm_sType
      application-data-type=s32MotorCurrentInmAType_Appl, implementation-data-type=s32MotorCurrentInmAType
      application-data-type=s32OrderValueType_Appl, implementation-data-type=s32OrderValueType
      application-data-type=s8MotorCurrentInAType_Appl, implementation-data-type=s8MotorCurrentInAType
      application-data-type=u16BoostPWMOrderType_Appl, implementation-data-type=u16BoostPWMOrderType
      application-data-type=u16BrakePressureType_Appl, implementation-data-type=u16BrakePressureType
      application-data-type=u16CurrentInLSBType_Appl, implementation-data-type=u16CurrentInLSBType
      application-data-type=u16InternalTemperatureType_Appl, implementation-data-type=u16InternalTemperatureType
      application-data-type=u16Resistance_mOhmType_Appl, implementation-data-type=u16Resistance_mOhmType
      application-data-type=u16SampledSignalType_Appl, implementation-data-type=u16SampledSignalType
      application-data-type=u16StepDurationType_Appl, implementation-data-type=u16StepDurationType
      application-data-type=u16VehicleSpeedType_Appl, implementation-data-type=u16VehicleSpeedType
      application-data-type=u8PwmChannelId_Appl, implementation-data-type=u8PwmChannelIdType
      application-data-type=u16NvmBlockIdType_Appl, implementation-data-type=NvM_ASR42_BlockIdType
      application-data-type=u8RequestResultType_Appl, implementation-data-type=NvM_ASR42_RequestResultType
package /AUTOLIV/GlobalDictionary/ImplementationDataTypes
  64 x impl type:
    b8AlgorithmFlagsStatusType: implementation-data-type=uint8
    b8BooleanType: implementation-data-type=uint8
    b8DefectStatusType: implementation-data-type=uint8
    b8IsCarAccelerationLowType: implementation-data-type=uint8
    b8IsCarCrankingActiveType: implementation-data-type=uint8
    b8IsCarCrashDetectedType: implementation-data-type=uint8
    b8PyroActivationStatusType: implementation-data-type=uint8
    s16AccelerationPedalPositionRateType: implementation-data-type=sint16
    s16AccelerationType: implementation-data-type=sint16
    s16AngleRateType: implementation-data-type=sint16
    s16BeltPosition_degType: implementation-data-type=sint16
    s16BeltPosition_mmType: implementation-data-type=sint16
    s16BrakePressureRateType: implementation-data-type=sint16
    s16HWAngleType: implementation-data-type=sint16
    s16HWRateType: implementation-data-type=sint16
    s16InternalTemperature_deg_Type: implementation-data-type=sint16
    s16MotorPowerOrderType: implementation-data-type=sint16
    s32BeltSpeed_deg_sType: implementation-data-type=sint32
    s32BeltSpeed_mm_sType: implementation-data-type=sint32
    s32MotorCurrentInmAType: implementation-data-type=sint32
    s32OrderValueType: implementation-data-type=sint32
    s8MotorCurrentInAType: implementation-data-type=sint8
    stAbsoluteSystemTimeType: category=STRUCTURE, sw-calibration-access=READ-ONLY
      element u32SystemTimeInSec: implementation-data-type=UInt32
      element u8SystemTimeOffset: implementation-data-type=UInt8
    u16BoostPWMOrderType: implementation-data-type=uint16
    u16BrakePressureType: implementation-data-type=uint16
    u16CurrentInLSBType: implementation-data-type=uint16
    u16InternalTemperatureType: implementation-data-type=uint16
    u16Resistance_mOhmType: implementation-data-type=uint16
    u16SampledSignalType: implementation-data-type=uint16
    u16StepDurationType: implementation-data-type=uint16
    u16VehicleSpeedType: implementation-data-type=uint16
    u16VoltageType: implementation-data-type=uint16
    u32DeficiencyLevelType: implementation-data-type=uint32
    u32ModeMaskType: implementation-data-type=uint32
    u32RelativeSystemTimeType: implementation-data-type=uint32
    u32ResetCauseType: implementation-data-type=uint32
    u32ResetReasonNotificationStatusType: implementation-data-type=uint32
    u32ResetReasonNotificationType: implementation-data-type=uint32
    u8AccelerationPedalPositionType: implementation-data-type=uint8
    u8AutoTestIdType: implementation-data-type=uint8
    u8BatteryVoltageSurveyStatusType: implementation-data-type=uint8
    u8BeltParkingAuthorizationStateType: implementation-data-type=uint8
    u8BeltSlackStatusType: implementation-data-type=uint8
    u8CanNmStateType: implementation-data-type=uint8
    u8CycleNumberType: implementation-data-type=uint8
    u8DoorSwitchStatusType: implementation-data-type=uint8
    u8EccErrorStatusType: implementation-data-type=uint8
    u8EccErrorType: implementation-data-type=uint8
    u8EsmEventIdType: implementation-data-type=uint8
    u8EsmStateType: implementation-data-type=uint8
    u8HapticRequestType: implementation-data-type=uint8
    u8KlemmenStatusType: implementation-data-type=uint8
    u8ModeStatusType: implementation-data-type=uint8
    u8MotorStageStatusType: implementation-data-type=uint8
    u8OrdersListType: implementation-data-type=uint8
    u8PreCrashRequestType: implementation-data-type=uint8
    u8PreCrashSeverityLevelType: implementation-data-type=uint8
    u8PwmChannelIdType: implementation-data-type=uint8
    u8RetractionStatusType: implementation-data-type=uint8
    u8SeverityLevelType: implementation-data-type=uint8
    u8StepNumberType: implementation-data-type=uint8
    u8TestResultType: implementation-data-type=uint8
    u8TriggeringSourceType: implementation-data-type=uint8
    u8lBuckleSwitchStatusType: implementation-data-type=uint8
package /AUTOLIV/GlobalDictionary/SenderReceiverInterfaces
  sender receiver interface isrAlgorithmFlagsStatus
    5 x data:
      b8TriggerFlag: type=b8AlgorithmFlagsStatusType_Appl  # State of the algorithm trigger flag
      b8InterruptFlag: type=b8AlgorithmFlagsStatusType_Appl  # State of the algorithm interrupt flag
      b8PreActivationFlag: type=b8AlgorithmFlagsStatusType_Appl
      b8PreConditionsFlag: type=b8AlgorithmFlagsStatusType_Appl  # State of the pre conditions related to the decision algorithm
      u8TriggeringSource: type=u8TriggeringSourceType_Appl  # Sources identifier requesting a belt function triggering.
  sender receiver interface isrCycleNumber
    data u8CycleNumber: type=u8CycleNumberType_Appl
package /AUTOLIV/GlobalDictionary/SwAddrMethods
  sw addr method CODE: memory-allocation-keyword-policy=ADDR-METHOD-SHORT-NAME, section-type=CODE
  sw addr method VAR: memory-allocation-keyword-policy=ADDR-METHOD-SHORT-NAME-AND-ALIGNMENT, section-initialization-policy=CLEARED, section-type=VAR
  sw addr method VAR_INIT: memory-allocation-keyword-policy=ADDR-METHOD-SHORT-NAME-AND-ALIGNMENT, section-initialization-policy=INIT, section-type=VAR
package /AUTOLIV/SoftwareComponents/BFS
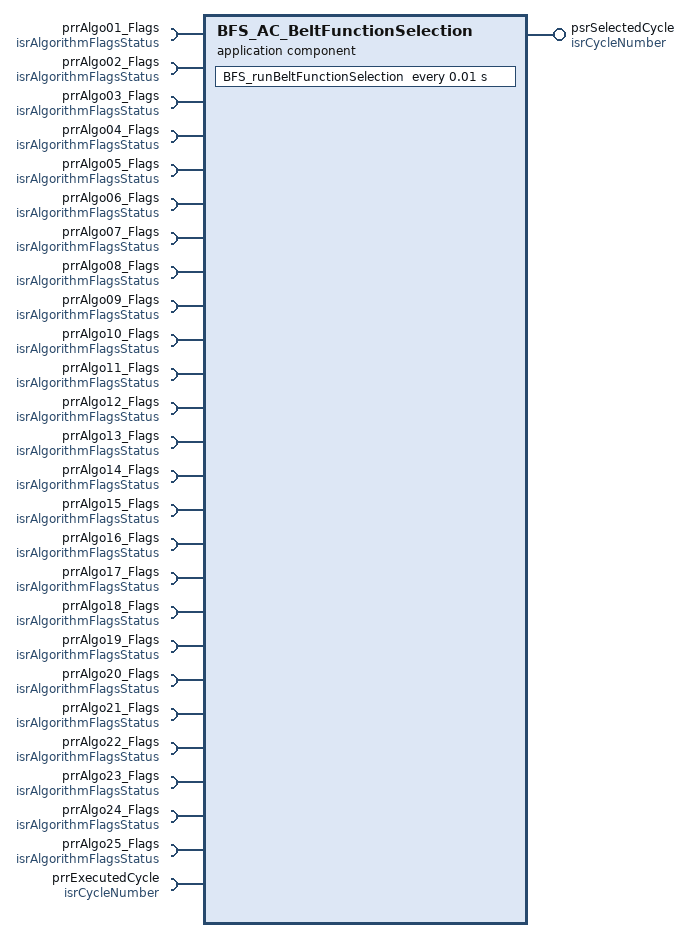
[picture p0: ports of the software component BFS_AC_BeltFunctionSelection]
  application sw component type BFS_AC_BeltFunctionSelection: category=SWC
    26 x require port:
      prrAlgo01_Flags: required-interface=isrAlgorithmFlagsStatus
        required-com-specs:
          data-element=b8TriggerFlag, uses-end-to-end-protection=0, init-value=constant-reference=APPLINIT_KB8_ALGO_FLAG_FALSE
          data-element=b8InterruptFlag, uses-end-to-end-protection=0, init-value=constant-reference=APPLINIT_KB8_ALGO_FLAG_FALSE
          data-element=b8PreActivationFlag, uses-end-to-end-protection=0, init-value=constant-reference=APPLINIT_KB8_ALGO_FLAG_FALSE
          data-element=b8PreConditionsFlag, uses-end-to-end-protection=0, init-value=constant-reference=APPLINIT_KB8_ALGO_FLAG_FALSE
          data-element=u8TriggeringSource, uses-end-to-end-protection=0, init-value=constant-reference=APPLINIT_KU8_TRIGGERING_SOURCE_NO
      prrAlgo02_Flags: required-interface=isrAlgorithmFlagsStatus
        required-com-specs:
          data-element=b8TriggerFlag, uses-end-to-end-protection=0, init-value=constant-reference=APPLINIT_KB8_ALGO_FLAG_FALSE
          data-element=b8InterruptFlag, uses-end-to-end-protection=0, init-value=constant-reference=APPLINIT_KB8_ALGO_FLAG_FALSE
          data-element=b8PreActivationFlag, uses-end-to-end-protection=0, init-value=constant-reference=APPLINIT_KB8_ALGO_FLAG_FALSE
          data-element=b8PreConditionsFlag, uses-end-to-end-protection=0, init-value=constant-reference=APPLINIT_KB8_ALGO_FLAG_FALSE
          data-element=u8TriggeringSource, uses-end-to-end-protection=0, init-value=constant-reference=APPLINIT_KU8_TRIGGERING_SOURCE_NO
      prrAlgo03_Flags: required-interface=isrAlgorithmFlagsStatus
        required-com-specs:
          data-element=b8TriggerFlag, uses-end-to-end-protection=0, init-value=constant-reference=APPLINIT_KB8_ALGO_FLAG_FALSE
          data-element=b8InterruptFlag, uses-end-to-end-protection=0, init-value=constant-reference=APPLINIT_KB8_ALGO_FLAG_FALSE
          data-element=b8PreActivationFlag, uses-end-to-end-protection=0, init-value=constant-reference=APPLINIT_KB8_ALGO_FLAG_FALSE
          data-element=b8PreConditionsFlag, uses-end-to-end-protection=0, init-value=constant-reference=APPLINIT_KB8_ALGO_FLAG_FALSE
          data-element=u8TriggeringSource, uses-end-to-end-protection=0, init-value=constant-reference=APPLINIT_KU8_TRIGGERING_SOURCE_NO
      prrAlgo04_Flags: required-interface=isrAlgorithmFlagsStatus
        required-com-specs:
          data-element=b8TriggerFlag, uses-end-to-end-protection=0, init-value=constant-reference=APPLINIT_KB8_ALGO_FLAG_FALSE
          data-element=b8InterruptFlag, uses-end-to-end-protection=0, init-value=constant-reference=APPLINIT_KB8_ALGO_FLAG_FALSE
          data-element=b8PreActivationFlag, uses-end-to-end-protection=0, init-value=constant-reference=APPLINIT_KB8_ALGO_FLAG_FALSE
          data-element=b8PreConditionsFlag, uses-end-to-end-protection=0, init-value=constant-reference=APPLINIT_KB8_ALGO_FLAG_FALSE
          data-element=u8TriggeringSource, uses-end-to-end-protection=0, init-value=constant-reference=APPLINIT_KU8_TRIGGERING_SOURCE_NO
      prrAlgo05_Flags: required-interface=isrAlgorithmFlagsStatus
        required-com-specs:
          data-element=b8TriggerFlag, uses-end-to-end-protection=0, init-value=constant-reference=APPLINIT_KB8_ALGO_FLAG_FALSE
          data-element=b8InterruptFlag, uses-end-to-end-protection=0, init-value=constant-reference=APPLINIT_KB8_ALGO_FLAG_FALSE
          data-element=b8PreActivationFlag, uses-end-to-end-protection=0, init-value=constant-reference=APPLINIT_KB8_ALGO_FLAG_FALSE
          data-element=b8PreConditionsFlag, uses-end-to-end-protection=0, init-value=constant-reference=APPLINIT_KB8_ALGO_FLAG_FALSE
          data-element=u8TriggeringSource, uses-end-to-end-protection=0, init-value=constant-reference=APPLINIT_KU8_TRIGGERING_SOURCE_NO
      prrAlgo06_Flags: required-interface=isrAlgorithmFlagsStatus
        required-com-specs:
          data-element=b8TriggerFlag, uses-end-to-end-protection=0, init-value=constant-reference=APPLINIT_KB8_ALGO_FLAG_FALSE
          data-element=b8InterruptFlag, uses-end-to-end-protection=0, init-value=constant-reference=APPLINIT_KB8_ALGO_FLAG_FALSE
          data-element=b8PreActivationFlag, uses-end-to-end-protection=0, init-value=constant-reference=APPLINIT_KB8_ALGO_FLAG_FALSE
          data-element=b8PreConditionsFlag, uses-end-to-end-protection=0, init-value=constant-reference=APPLINIT_KB8_ALGO_FLAG_FALSE
          data-element=u8TriggeringSource, uses-end-to-end-protection=0, init-value=constant-reference=APPLINIT_KU8_TRIGGERING_SOURCE_NO
      prrAlgo07_Flags: required-interface=isrAlgorithmFlagsStatus
        required-com-specs:
          data-element=b8TriggerFlag, uses-end-to-end-protection=0, init-value=constant-reference=APPLINIT_KB8_ALGO_FLAG_FALSE
          data-element=b8InterruptFlag, uses-end-to-end-protection=0, init-value=constant-reference=APPLINIT_KB8_ALGO_FLAG_FALSE
          data-element=b8PreActivationFlag, uses-end-to-end-protection=0, init-value=constant-reference=APPLINIT_KB8_ALGO_FLAG_FALSE
          data-element=b8PreConditionsFlag, uses-end-to-end-protection=0, init-value=constant-reference=APPLINIT_KB8_ALGO_FLAG_FALSE
          data-element=u8TriggeringSource, uses-end-to-end-protection=0, init-value=constant-reference=APPLINIT_KU8_TRIGGERING_SOURCE_NO
      prrAlgo08_Flags: required-interface=isrAlgorithmFlagsStatus
        required-com-specs:
          data-element=b8TriggerFlag, uses-end-to-end-protection=0, init-value=constant-reference=APPLINIT_KB8_ALGO_FLAG_FALSE
          data-element=b8InterruptFlag, uses-end-to-end-protection=0, init-value=constant-reference=APPLINIT_KB8_ALGO_FLAG_FALSE
          data-element=b8PreActivationFlag, uses-end-to-end-protection=0, init-value=constant-reference=APPLINIT_KB8_ALGO_FLAG_FALSE
          data-element=b8PreConditionsFlag, uses-end-to-end-protection=0, init-value=constant-reference=APPLINIT_KB8_ALGO_FLAG_FALSE
          data-element=u8TriggeringSource, uses-end-to-end-protection=0, init-value=constant-reference=APPLINIT_KU8_TRIGGERING_SOURCE_NO
      prrAlgo09_Flags: required-interface=isrAlgorithmFlagsStatus
        required-com-specs:
          data-element=b8TriggerFlag, uses-end-to-end-protection=0, init-value=constant-reference=APPLINIT_KB8_ALGO_FLAG_FALSE
          data-element=b8InterruptFlag, uses-end-to-end-protection=0, init-value=constant-reference=APPLINIT_KB8_ALGO_FLAG_FALSE
          data-element=b8PreActivationFlag, uses-end-to-end-protection=0, init-value=constant-reference=APPLINIT_KB8_ALGO_FLAG_FALSE
          data-element=b8PreConditionsFlag, uses-end-to-end-protection=0, init-value=constant-reference=APPLINIT_KB8_ALGO_FLAG_FALSE
          data-element=u8TriggeringSource, uses-end-to-end-protection=0, init-value=constant-reference=APPLINIT_KU8_TRIGGERING_SOURCE_NO
      prrAlgo10_Flags: required-interface=isrAlgorithmFlagsStatus
        required-com-specs:
          data-element=b8TriggerFlag, uses-end-to-end-protection=0, init-value=constant-reference=APPLINIT_KB8_ALGO_FLAG_FALSE
          data-element=b8InterruptFlag, uses-end-to-end-protection=0, init-value=constant-reference=APPLINIT_KB8_ALGO_FLAG_FALSE
          data-element=b8PreActivationFlag, uses-end-to-end-protection=0, init-value=constant-reference=APPLINIT_KB8_ALGO_FLAG_FALSE
          data-element=b8PreConditionsFlag, uses-end-to-end-protection=0, init-value=constant-reference=APPLINIT_KB8_ALGO_FLAG_FALSE
          data-element=u8TriggeringSource, uses-end-to-end-protection=0, init-value=constant-reference=APPLINIT_KU8_TRIGGERING_SOURCE_NO
      prrAlgo11_Flags: required-interface=isrAlgorithmFlagsStatus
        required-com-specs:
          data-element=b8TriggerFlag, uses-end-to-end-protection=0, init-value=constant-reference=APPLINIT_KB8_ALGO_FLAG_FALSE
          data-element=b8InterruptFlag, uses-end-to-end-protection=0, init-value=constant-reference=APPLINIT_KB8_ALGO_FLAG_FALSE
          data-element=b8PreActivationFlag, uses-end-to-end-protection=0, init-value=constant-reference=APPLINIT_KB8_ALGO_FLAG_FALSE
          data-element=b8PreConditionsFlag, uses-end-to-end-protection=0, init-value=constant-reference=APPLINIT_KB8_ALGO_FLAG_FALSE
          data-element=u8TriggeringSource, uses-end-to-end-protection=0, init-value=constant-reference=APPLINIT_KU8_TRIGGERING_SOURCE_NO
      prrAlgo12_Flags: required-interface=isrAlgorithmFlagsStatus
        required-com-specs:
          data-element=b8TriggerFlag, uses-end-to-end-protection=0, init-value=constant-reference=APPLINIT_KB8_ALGO_FLAG_FALSE
          data-element=b8InterruptFlag, uses-end-to-end-protection=0, init-value=constant-reference=APPLINIT_KB8_ALGO_FLAG_FALSE
          data-element=b8PreActivationFlag, uses-end-to-end-protection=0, init-value=constant-reference=APPLINIT_KB8_ALGO_FLAG_FALSE
          data-element=b8PreConditionsFlag, uses-end-to-end-protection=0, init-value=constant-reference=APPLINIT_KB8_ALGO_FLAG_FALSE
          data-element=u8TriggeringSource, uses-end-to-end-protection=0, init-value=constant-reference=APPLINIT_KU8_TRIGGERING_SOURCE_NO
      prrAlgo13_Flags: required-interface=isrAlgorithmFlagsStatus
        required-com-specs:
          data-element=b8TriggerFlag, uses-end-to-end-protection=0, init-value=constant-reference=APPLINIT_KB8_ALGO_FLAG_FALSE
          data-element=b8InterruptFlag, uses-end-to-end-protection=0, init-value=constant-reference=APPLINIT_KB8_ALGO_FLAG_FALSE
          data-element=b8PreActivationFlag, uses-end-to-end-protection=0, init-value=constant-reference=APPLINIT_KB8_ALGO_FLAG_FALSE
          data-element=b8PreConditionsFlag, uses-end-to-end-protection=0, init-value=constant-reference=APPLINIT_KB8_ALGO_FLAG_FALSE
          data-element=u8TriggeringSource, uses-end-to-end-protection=0, init-value=constant-reference=APPLINIT_KU8_TRIGGERING_SOURCE_NO
      prrAlgo14_Flags: required-interface=isrAlgorithmFlagsStatus
        required-com-specs:
          data-element=b8TriggerFlag, uses-end-to-end-protection=0, init-value=constant-reference=APPLINIT_KB8_ALGO_FLAG_FALSE
          data-element=b8InterruptFlag, uses-end-to-end-protection=0, init-value=constant-reference=APPLINIT_KB8_ALGO_FLAG_FALSE
          data-element=b8PreActivationFlag, uses-end-to-end-protection=0, init-value=constant-reference=APPLINIT_KB8_ALGO_FLAG_FALSE
          data-element=b8PreConditionsFlag, uses-end-to-end-protection=0, init-value=constant-reference=APPLINIT_KB8_ALGO_FLAG_FALSE
          data-element=u8TriggeringSource, uses-end-to-end-protection=0, init-value=constant-reference=APPLINIT_KU8_TRIGGERING_SOURCE_NO
      prrAlgo15_Flags: required-interface=isrAlgorithmFlagsStatus
        required-com-specs:
          data-element=b8TriggerFlag, uses-end-to-end-protection=0, init-value=constant-reference=APPLINIT_KB8_ALGO_FLAG_FALSE
          data-element=b8InterruptFlag, uses-end-to-end-protection=0, init-value=constant-reference=APPLINIT_KB8_ALGO_FLAG_FALSE
          data-element=b8PreActivationFlag, uses-end-to-end-protection=0, init-value=constant-reference=APPLINIT_KB8_ALGO_FLAG_FALSE
          data-element=b8PreConditionsFlag, uses-end-to-end-protection=0, init-value=constant-reference=APPLINIT_KB8_ALGO_FLAG_FALSE
          data-element=u8TriggeringSource, uses-end-to-end-protection=0, init-value=constant-reference=APPLINIT_KU8_TRIGGERING_SOURCE_NO
      prrAlgo16_Flags: required-interface=isrAlgorithmFlagsStatus
        required-com-specs:
          data-element=b8TriggerFlag, uses-end-to-end-protection=0, init-value=constant-reference=APPLINIT_KB8_ALGO_FLAG_FALSE
          data-element=b8InterruptFlag, uses-end-to-end-protection=0, init-value=constant-reference=APPLINIT_KB8_ALGO_FLAG_FALSE
          data-element=b8PreActivationFlag, uses-end-to-end-protection=0, init-value=constant-reference=APPLINIT_KB8_ALGO_FLAG_FALSE
          data-element=b8PreConditionsFlag, uses-end-to-end-protection=0, init-value=constant-reference=APPLINIT_KB8_ALGO_FLAG_FALSE
          data-element=u8TriggeringSource, uses-end-to-end-protection=0, init-value=constant-reference=APPLINIT_KU8_TRIGGERING_SOURCE_NO
      prrAlgo17_Flags: required-interface=isrAlgorithmFlagsStatus
        required-com-specs:
          data-element=b8TriggerFlag, uses-end-to-end-protection=0, init-value=constant-reference=APPLINIT_KB8_ALGO_FLAG_FALSE
          data-element=b8InterruptFlag, uses-end-to-end-protection=0, init-value=constant-reference=APPLINIT_KB8_ALGO_FLAG_FALSE
          data-element=b8PreActivationFlag, uses-end-to-end-protection=0, init-value=constant-reference=APPLINIT_KB8_ALGO_FLAG_FALSE
          data-element=b8PreConditionsFlag, uses-end-to-end-protection=0, init-value=constant-reference=APPLINIT_KB8_ALGO_FLAG_FALSE
          data-element=u8TriggeringSource, uses-end-to-end-protection=0, init-value=constant-reference=APPLINIT_KU8_TRIGGERING_SOURCE_NO
      prrAlgo18_Flags: required-interface=isrAlgorithmFlagsStatus
        required-com-specs:
          data-element=b8TriggerFlag, uses-end-to-end-protection=0, init-value=constant-reference=APPLINIT_KB8_ALGO_FLAG_FALSE
          data-element=b8InterruptFlag, uses-end-to-end-protection=0, init-value=constant-reference=APPLINIT_KB8_ALGO_FLAG_FALSE
          data-element=b8PreActivationFlag, uses-end-to-end-protection=0, init-value=constant-reference=APPLINIT_KB8_ALGO_FLAG_FALSE
          data-element=b8PreConditionsFlag, uses-end-to-end-protection=0, init-value=constant-reference=APPLINIT_KB8_ALGO_FLAG_FALSE
          data-element=u8TriggeringSource, uses-end-to-end-protection=0, init-value=constant-reference=APPLINIT_KU8_TRIGGERING_SOURCE_NO
      prrAlgo19_Flags: required-interface=isrAlgorithmFlagsStatus
        required-com-specs:
          data-element=b8TriggerFlag, uses-end-to-end-protection=0, init-value=constant-reference=APPLINIT_KB8_ALGO_FLAG_FALSE
          data-element=b8InterruptFlag, uses-end-to-end-protection=0, init-value=constant-reference=APPLINIT_KB8_ALGO_FLAG_FALSE
          data-element=b8PreActivationFlag, uses-end-to-end-protection=0, init-value=constant-reference=APPLINIT_KB8_ALGO_FLAG_FALSE
          data-element=b8PreConditionsFlag, uses-end-to-end-protection=0, init-value=constant-reference=APPLINIT_KB8_ALGO_FLAG_FALSE
          data-element=u8TriggeringSource, uses-end-to-end-protection=0, init-value=constant-reference=APPLINIT_KU8_TRIGGERING_SOURCE_NO
      prrAlgo20_Flags: required-interface=isrAlgorithmFlagsStatus
        required-com-specs:
          data-element=b8TriggerFlag, uses-end-to-end-protection=0, init-value=constant-reference=APPLINIT_KB8_ALGO_FLAG_FALSE
          data-element=b8InterruptFlag, uses-end-to-end-protection=0, init-value=constant-reference=APPLINIT_KB8_ALGO_FLAG_FALSE
          data-element=b8PreActivationFlag, uses-end-to-end-protection=0, init-value=constant-reference=APPLINIT_KB8_ALGO_FLAG_FALSE
          data-element=b8PreConditionsFlag, uses-end-to-end-protection=0, init-value=constant-reference=APPLINIT_KB8_ALGO_FLAG_FALSE
          data-element=u8TriggeringSource, uses-end-to-end-protection=0, init-value=constant-reference=APPLINIT_KU8_TRIGGERING_SOURCE_NO
      prrAlgo21_Flags: required-interface=isrAlgorithmFlagsStatus
        required-com-specs:
          data-element=b8TriggerFlag, uses-end-to-end-protection=0, init-value=constant-reference=APPLINIT_KB8_ALGO_FLAG_FALSE
          data-element=b8InterruptFlag, uses-end-to-end-protection=0, init-value=constant-reference=APPLINIT_KB8_ALGO_FLAG_FALSE
          data-element=b8PreActivationFlag, uses-end-to-end-protection=0, init-value=constant-reference=APPLINIT_KB8_ALGO_FLAG_FALSE
          data-element=b8PreConditionsFlag, uses-end-to-end-protection=0, init-value=constant-reference=APPLINIT_KB8_ALGO_FLAG_FALSE
          data-element=u8TriggeringSource, uses-end-to-end-protection=0, init-value=constant-reference=APPLINIT_KU8_TRIGGERING_SOURCE_NO
      prrAlgo22_Flags: required-interface=isrAlgorithmFlagsStatus
        required-com-specs:
          data-element=b8TriggerFlag, uses-end-to-end-protection=0, init-value=constant-reference=APPLINIT_KB8_ALGO_FLAG_FALSE
          data-element=b8InterruptFlag, uses-end-to-end-protection=0, init-value=constant-reference=APPLINIT_KB8_ALGO_FLAG_FALSE
          data-element=b8PreActivationFlag, uses-end-to-end-protection=0, init-value=constant-reference=APPLINIT_KB8_ALGO_FLAG_FALSE
          data-element=b8PreConditionsFlag, uses-end-to-end-protection=0, init-value=constant-reference=APPLINIT_KB8_ALGO_FLAG_FALSE
          data-element=u8TriggeringSource, uses-end-to-end-protection=0, init-value=constant-reference=APPLINIT_KU8_TRIGGERING_SOURCE_NO
      prrAlgo23_Flags: required-interface=isrAlgorithmFlagsStatus
        required-com-specs:
          data-element=b8TriggerFlag, uses-end-to-end-protection=0, init-value=constant-reference=APPLINIT_KB8_ALGO_FLAG_FALSE
          data-element=b8InterruptFlag, uses-end-to-end-protection=0, init-value=constant-reference=APPLINIT_KB8_ALGO_FLAG_FALSE
          data-element=b8PreActivationFlag, uses-end-to-end-protection=0, init-value=constant-reference=APPLINIT_KB8_ALGO_FLAG_FALSE
          data-element=b8PreConditionsFlag, uses-end-to-end-protection=0, init-value=constant-reference=APPLINIT_KB8_ALGO_FLAG_FALSE
          data-element=u8TriggeringSource, uses-end-to-end-protection=0, init-value=constant-reference=APPLINIT_KU8_TRIGGERING_SOURCE_NO
      prrAlgo24_Flags: required-interface=isrAlgorithmFlagsStatus
        required-com-specs:
          data-element=b8TriggerFlag, uses-end-to-end-protection=0, init-value=constant-reference=APPLINIT_KB8_ALGO_FLAG_FALSE
          data-element=b8InterruptFlag, uses-end-to-end-protection=0, init-value=constant-reference=APPLINIT_KB8_ALGO_FLAG_FALSE
          data-element=b8PreActivationFlag, uses-end-to-end-protection=0, init-value=constant-reference=APPLINIT_KB8_ALGO_FLAG_FALSE
          data-element=b8PreConditionsFlag, uses-end-to-end-protection=0, init-value=constant-reference=APPLINIT_KB8_ALGO_FLAG_FALSE
          data-element=u8TriggeringSource, uses-end-to-end-protection=0, init-value=constant-reference=APPLINIT_KU8_TRIGGERING_SOURCE_NO
      prrAlgo25_Flags: required-interface=isrAlgorithmFlagsStatus
        required-com-specs:
          data-element=b8TriggerFlag, uses-end-to-end-protection=0, init-value=constant-reference=APPLINIT_KB8_ALGO_FLAG_FALSE
          data-element=b8InterruptFlag, uses-end-to-end-protection=0, init-value=constant-reference=APPLINIT_KB8_ALGO_FLAG_FALSE
          data-element=b8PreActivationFlag, uses-end-to-end-protection=0, init-value=constant-reference=APPLINIT_KB8_ALGO_FLAG_FALSE
          data-element=b8PreConditionsFlag, uses-end-to-end-protection=0, init-value=constant-reference=APPLINIT_KB8_ALGO_FLAG_FALSE
          data-element=u8TriggeringSource, uses-end-to-end-protection=0, init-value=constant-reference=APPLINIT_KU8_TRIGGERING_SOURCE_NO
      prrExecutedCycle: nonqueued-receiver-com-spec{data-element=u8CycleNumber, uses-end-to-end-protection=0, init-value=constant-reference=APPLINIT_KU8_CYCLE_NUMBER_NONE}, required-interface=isrCycleNumber
    provide port psrSelectedCycle: nonqueued-sender-com-spec{data-element=u8CycleNumber, uses-end-to-end-protection=0, init-value=constant-reference=APPLINIT_KU8_CYCLE_NUMBER_NONE}, provided-interface=isrCycleNumber
    behavior BFS_IB_BeltFunctionSelection: constant-value-mapping=ConstantsMappingSet_PP4G, data-type-mapping=DataTypeMappingSet_PP4G, handle-termination-and-restart=NO-SUPPORT
      timing event BFS_evBeltFunctionSelection: start-on-event=BFS_runBeltFunctionSelection, period=0.01
      runnable BFS_runBeltFunctionSelection
        data-read-access:
          access DRA_prrExecut_u8CycleNumber: accessed-variable=prrExecutedCycle.u8CycleNumber  # ARCH_SW_BFS_0090
        data-receive-point-by-arguments:
          50 x access:
            DRP_prrAlgo13_InterruptFlag: accessed-variable=prrAlgo13_Flags.b8InterruptFlag  # ARCH_SW_BFS_0056
            DRP_prrAlgo22_b8TriggerFlag: accessed-variable=prrAlgo22_Flags.b8TriggerFlag
            DRP_prrAlgo23_InterruptFlag: accessed-variable=prrAlgo23_Flags.b8InterruptFlag
            DRP_prrAlgo21_b8TriggerFlag: accessed-variable=prrAlgo21_Flags.b8TriggerFlag  # ARCH_SW_BFS_0082
            DRP_prrAlgo05_InterruptFlag: accessed-variable=prrAlgo05_Flags.b8InterruptFlag  # ARCH_SW_BFS_0035
            DRP_prrAlgo07_b8TriggerFlag: accessed-variable=prrAlgo07_Flags.b8TriggerFlag  # ARCH_SW_BFS_0027
            DRP_prrAlgo25_b8TriggerFlag: accessed-variable=prrAlgo25_Flags.b8TriggerFlag
            DRP_prrAlgo23_b8TriggerFlag: accessed-variable=prrAlgo23_Flags.b8TriggerFlag
            DRP_prrAlgo10_b8TriggerFlag: accessed-variable=prrAlgo10_Flags.b8TriggerFlag
            DRP_prrAlgo12_b8TriggerFlag: accessed-variable=prrAlgo12_Flags.b8TriggerFlag  # ARCH_SW_BFS_0052
            DRP_prrAlgo20_b8TriggerFlag: accessed-variable=prrAlgo20_Flags.b8TriggerFlag  # ARCH_SW_BFS_0081
            DRP_prrAlgo15_b8TriggerFlag: accessed-variable=prrAlgo15_Flags.b8TriggerFlag  # ARCH_SW_BFS_0062
            DRP_prrAlgo01_InterruptFlag: accessed-variable=prrAlgo01_Flags.b8InterruptFlag  # ARCH_SW_BFS_0031
            DRP_prrAlgo01_b8TriggerFlag: accessed-variable=prrAlgo01_Flags.b8TriggerFlag  # ARCH_SW_BFS_0021
            DRP_prrAlgo19_InterruptFlag: accessed-variable=prrAlgo19_Flags.b8InterruptFlag  # ARCH_SW_BFS_0078
            DRP_prrAlgo17_b8TriggerFlag: accessed-variable=prrAlgo17_Flags.b8TriggerFlag  # ARCH_SW_BFS_0072
            DRP_prrAlgo07_InterruptFlag: accessed-variable=prrAlgo07_Flags.b8InterruptFlag  # ARCH_SW_BFS_0037
            DRP_prrAlgo03_InterruptFlag: accessed-variable=prrAlgo03_Flags.b8InterruptFlag  # ARCH_SW_BFS_0033
            DRP_prrAlgo19_b8TriggerFlag: accessed-variable=prrAlgo19_Flags.b8TriggerFlag  # ARCH_SW_BFS_0074
            DRP_prrAlgo06_b8TriggerFlag: accessed-variable=prrAlgo06_Flags.b8TriggerFlag  # ARCH_SW_BFS_0026
            DRP_prrAlgo11_b8TriggerFlag: accessed-variable=prrAlgo11_Flags.b8TriggerFlag  # ARCH_SW_BFS_0051
            DRP_prrAlgo06_InterruptFlag: accessed-variable=prrAlgo06_Flags.b8InterruptFlag  # ARCH_SW_BFS_0036
            DRP_prrAlgo12_InterruptFlag: accessed-variable=prrAlgo12_Flags.b8InterruptFlag  # ARCH_SW_BFS_0055
            DRP_prrAlgo11_InterruptFlag: accessed-variable=prrAlgo11_Flags.b8InterruptFlag  # ARCH_SW_BFS_0054
            DRP_prrAlgo10_InterruptFlag: accessed-variable=prrAlgo10_Flags.b8InterruptFlag
            DRP_prrAlgo17_InterruptFlag: accessed-variable=prrAlgo17_Flags.b8InterruptFlag  # ARCH_SW_BFS_0076
            DRP_prrAlgo13_b8TriggerFlag: accessed-variable=prrAlgo13_Flags.b8TriggerFlag  # ARCH_SW_BFS_0053
            DRP_prrAlgo09_InterruptFlag: accessed-variable=prrAlgo09_Flags.b8InterruptFlag  # ARCH_SW_BFS_0042
            DRP_prrAlgo02_b8TriggerFlag: accessed-variable=prrAlgo02_Flags.b8TriggerFlag  # ARCH_SW_BFS_0022
            DRP_prrAlgo24_b8TriggerFlag: accessed-variable=prrAlgo24_Flags.b8TriggerFlag
            DRP_prrAlgo25_InterruptFlag: accessed-variable=prrAlgo25_Flags.b8InterruptFlag
            DRP_prrAlgo20_InterruptFlag: accessed-variable=prrAlgo20_Flags.b8InterruptFlag  # ARCH_SW_BFS_0084
            DRP_prrAlgo24_InterruptFlag: accessed-variable=prrAlgo24_Flags.b8InterruptFlag
            DRP_prrAlgo21_InterruptFlag: accessed-variable=prrAlgo21_Flags.b8InterruptFlag  # ARCH_SW_BFS_0085
            DRP_prrAlgo15_InterruptFlag: accessed-variable=prrAlgo15_Flags.b8InterruptFlag  # ARCH_SW_BFS_0065
            DRP_prrAlgo02_InterruptFlag: accessed-variable=prrAlgo02_Flags.b8InterruptFlag  # ARCH_SW_BFS_0032
            DRP_prrAlgo05_b8TriggerFlag: accessed-variable=prrAlgo05_Flags.b8TriggerFlag  # ARCH_SW_BFS_0025
            DRP_prrAlgo04_InterruptFlag: accessed-variable=prrAlgo04_Flags.b8InterruptFlag  # ARCH_SW_BFS_0034
            DRP_prrAlgo14_InterruptFlag: accessed-variable=prrAlgo14_Flags.b8InterruptFlag  # ARCH_SW_BFS_0064
            DRP_prrAlgo04_b8TriggerFlag: accessed-variable=prrAlgo04_Flags.b8TriggerFlag  # ARCH_SW_BFS_0024
            DRP_prrAlgo18_InterruptFlag: accessed-variable=prrAlgo18_Flags.b8InterruptFlag  # ARCH_SW_BFS_0077
            DRP_prrAlgo14_b8TriggerFlag: accessed-variable=prrAlgo14_Flags.b8TriggerFlag  # ARCH_SW_BFS_0061
            DRP_prrAlgo16_b8TriggerFlag: accessed-variable=prrAlgo16_Flags.b8TriggerFlag  # ARCH_SW_BFS_0071
            DRP_prrAlgo09_b8TriggerFlag: accessed-variable=prrAlgo09_Flags.b8TriggerFlag  # ARCH_SW_BFS_0041
            DRP_prrAlgo08_b8TriggerFlag: accessed-variable=prrAlgo08_Flags.b8TriggerFlag  # ARCH_SW_BFS_0028
            DRP_prrAlgo18_b8TriggerFlag: accessed-variable=prrAlgo18_Flags.b8TriggerFlag  # ARCH_SW_BFS_0073
            DRP_prrAlgo22_InterruptFlag: accessed-variable=prrAlgo22_Flags.b8InterruptFlag
            DRP_prrAlgo03_b8TriggerFlag: accessed-variable=prrAlgo03_Flags.b8TriggerFlag  # ARCH_SW_BFS_0023
            DRP_prrAlgo16_InterruptFlag: accessed-variable=prrAlgo16_Flags.b8InterruptFlag  # ARCH_SW_BFS_0075
            DRP_prrAlgo08_InterruptFlag: accessed-variable=prrAlgo08_Flags.b8InterruptFlag  # ARCH_SW_BFS_0038
        data-send-points:
          access DSP_psrSelect_u8CycleNumber: accessed-variable=psrSelectedCycle.u8CycleNumber  # ARCH_SW_BFS_0091
  swc implementation BFS_impBeltFunctionSelection: programming-language=C, sw-version=1.0.0, vendor-id=0, behavior=BFS_IB_BeltFunctionSelection
    code-descriptors:
      code BFS_Impl_Code: artifact-descriptors=autosar-engineering-object={short-label=BFS_Impl_Code_CodeDesc, category=SWSRC}
    resource consumption BFS_Impl_ResCons
      memory section CODE: size=0, sw-addrmethod=CODE
      memory section VAR_INIT_UNSPECIFIED: alignment=UNSPECIFIED, size=0, sw-addrmethod=VAR_INIT
      memory section VAR_UNSPECIFIED: alignment=UNSPECIFIED, size=0, sw-addrmethod=VAR
package /AUTOSAR/AISpecification/PhysicalDimensions
  physical dimension NoDimension  # No Dimension
package /AUTOSAR/AISpecification/Units
  unit NoUnit: display-name=-, factor-si-to-unit=1.0, physical-dimension=NoDimension  # No Unit | Unit for dimensionless continuous value data types like numbers, factors and coefficients
package /AUTOSAR_NvM/ASR42/ImplementationDataTypes
  impl type NvM_ASR42_BlockIdType: implementation-data-type=uint16
  impl type NvM_ASR42_RequestResultType: compu {0=NVM_REQ_OK, 1=NVM_REQ_NOT_OK, 2=NVM_REQ_PENDING, 3=NVM_REQ_INTEGRITY_FAILED, 4=NVM_REQ_BLOCK_SKIPPED, 5=NVM_REQ_NV_INVALIDATED, 6=NVM_REQ_CANCELED, 7=NVM_REQ_REDUNDANCY_FAILED, 8=NVM_REQ_RESTORED_FROM_ROM}, implementation-data-type=uint8
package /Constants
  constant specification APPLINIT_KU8_UINT8_ZERO: value-spec=0
  constant specification IMPLINIT_KU8_UINT8_ZERO: value-spec=0
